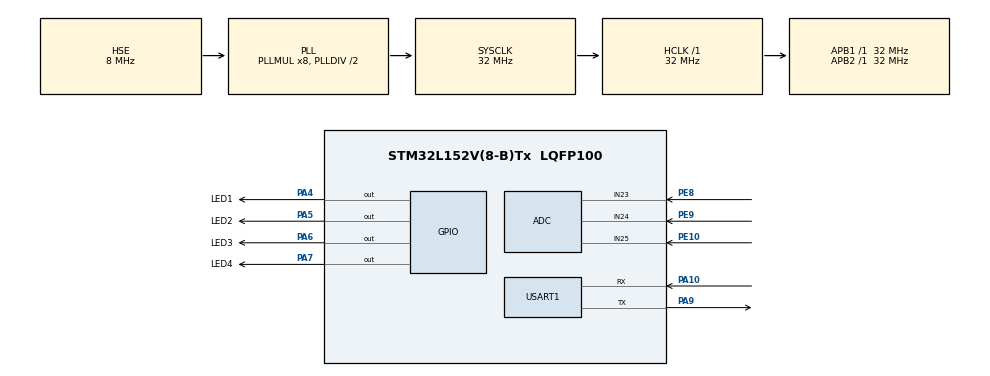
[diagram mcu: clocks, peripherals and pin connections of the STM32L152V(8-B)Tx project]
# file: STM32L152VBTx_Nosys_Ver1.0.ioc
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ADC.Channel-8\#ChannelRegularConversion=ADC_CHANNEL_25
ADC.NbrOfConversionFlag=1
ADC.Rank-8\#ChannelRegularConversion=1
ADC.SamplingTime-8\#ChannelRegularConversion=ADC_SAMPLETIME_4CYCLES
Mcu.Family=STM32L1
Mcu.Name=STM32L152V(8-B)Tx
Mcu.Package=LQFP100
NVIC.PriorityGroup=NVIC_PRIORITYGROUP_4
PA10.Mode=Asynchronous
PA10.Signal=USART1_RX
PA4.GPIO_Label=LED1
PA4.GPIO_ModeDefaultOutputPP=GPIO_MODE_OUTPUT_PP
PA4.GPIO_PuPd=GPIO_PULLUP
PA4.GPIO_Speed=GPIO_SPEED_FREQ_LOW
PA4.Signal=GPIO_Output
PA5.GPIO_Label=LED2
PA5.GPIO_PuPd=GPIO_PULLUP
PA5.Signal=GPIO_Output
PA6.GPIO_Label=LED3
PA6.GPIO_PuPd=GPIO_PULLUP
PA6.Signal=GPIO_Output
PA7.GPIO_Label=LED4
PA7.GPIO_PuPd=GPIO_PULLUP
PA7.Signal=GPIO_Output
PA9.Mode=Asynchronous
PA9.Signal=USART1_TX
PE10.Mode=IN25
PE10.Signal=ADC_IN25
PE8.Mode=IN23
PE8.Signal=ADC_IN23
PE9.Mode=IN24
PE9.Signal=ADC_IN24
PH0-OSC_IN.Mode=HSE-External-Oscillator
PH0-OSC_IN.Signal=RCC_OSC_IN
PH1-OSC_OUT.Mode=HSE-External-Oscillator
PH1-OSC_OUT.Signal=RCC_OSC_OUT
ProjectManager.HeapSize=0x200
ProjectManager.StackSize=0x400
ProjectManager.TargetToolchain=MDK-ARM V5
RCC.AHBFreq_Value=32000000
RCC.APB1Freq_Value=32000000
RCC.APB1TimFreq_Value=32000000
RCC.APB2Freq_Value=32000000
RCC.APB2TimFreq_Value=32000000
RCC.HCLKFreq_Value=32000000
RCC.HSE_VALUE=8000000
RCC.HSI_VALUE=16000000
RCC.LSE_VALUE=32768
RCC.MSI_VALUE=2097000
RCC.PLLMUL=RCC_PLL_MUL8
RCC.PLLSourceVirtual=RCC_PLLSOURCE_HSE
RCC.SYSCLKFreq_VALUE=32000000
RCC.SYSCLKSource=RCC_SYSCLKSOURCE_PLLCLK
RCC.USBOutput=32000000
RCC.VCOOutputFreq_Value=64000000
board=STM32L152VBTx_Nosys_Ver1.0

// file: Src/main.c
/**
  ******************************************************************************
  * File Name          : main.c
  * Description        : Main program body
  ******************************************************************************
  *
  * COPYRIGHT(c) 2017 STMicroelectronics
  *
  * Redistribution and use in source and binary forms, with or without modification,
  * are permitted provided that the following conditions are met:
  *   1. Redistributions of source code must retain the above copyright notice,
  *      this list of conditions and the following disclaimer.
  *   2. Redistributions in binary form must reproduce the above copyright notice,
  *      this list of conditions and the following disclaimer in the documentation
  *      and/or other materials provided with the distribution.
  *   3. Neither the name of STMicroelectronics nor the names of its contributors
  *      may be used to endorse or promote products derived from this software
  *      without specific prior written permission.
  *
  * THIS SOFTWARE IS PROVIDED BY THE COPYRIGHT HOLDERS AND CONTRIBUTORS "AS IS"
  * AND ANY EXPRESS OR IMPLIED WARRANTIES, INCLUDING, BUT NOT LIMITED TO, THE
  * IMPLIED WARRANTIES OF MERCHANTABILITY AND FITNESS FOR A PARTICULAR PURPOSE ARE
  * DISCLAIMED. IN NO EVENT SHALL THE COPYRIGHT HOLDER OR CONTRIBUTORS BE LIABLE
  * FOR ANY DIRECT, INDIRECT, INCIDENTAL, SPECIAL, EXEMPLARY, OR CONSEQUENTIAL
  * DAMAGES (INCLUDING, BUT NOT LIMITED TO, PROCUREMENT OF SUBSTITUTE GOODS OR
  * SERVICES; LOSS OF USE, DATA, OR PROFITS; OR BUSINESS INTERRUPTION) HOWEVER
  * CAUSED AND ON ANY THEORY OF LIABILITY, WHETHER IN CONTRACT, STRICT LIABILITY,
  * OR TORT (INCLUDING NEGLIGENCE OR OTHERWISE) ARISING IN ANY WAY OUT OF THE USE
  * OF THIS SOFTWARE, EVEN IF ADVISED OF THE POSSIBILITY OF SUCH DAMAGE.
  *
  ******************************************************************************
  */
#include "main.h"
#include "stm32l1xx_hal.h"
#include "adc.h"
#include "usart.h"
#include "gpio.h"

/* USER CODE BEGIN PV */
/* Private variables ---------------------------------------------------------*/

/* USER CODE END PV */

void SystemClock_Config(void);
void Error_Handler(void);

/* USER CODE BEGIN PFP */
/* Private function prototypes -----------------------------------------------*/

/* USER CODE END PFP */

int main(void)
{

  /* USER CODE BEGIN 1 */
	uint8_t u8DataSend[64] = "Hello the world \n";
  /* USER CODE END 1 */

  /* MCU Configuration----------------------------------------------------------*/

  /* Reset of all peripherals, Initializes the Flash interface and the Systick. */
  HAL_Init();

  /* Configure the system clock */
  SystemClock_Config();

  /* Initialize all configured peripherals */
  MX_GPIO_Init();
  MX_ADC_Init();
  MX_USART1_UART_Init();

  /* USER CODE BEGIN 2 */
  //why leave my love?
  /* USER CODE END 2 */

  /* Infinite loop */
  while (1)
  {
		  HAL_Delay(100);
			HAL_GPIO_TogglePin(GPIOA, LED1_Pin);
		  HAL_GPIO_TogglePin(GPIOA, LED2_Pin);
		  HAL_Delay(100);

		  HAL_UART_Transmit(&huart1, u8DataSend, sizeof(u8DataSend), 1000);
      HAL_Delay(1000);

  }

}

/** System Clock Configuration
*/
void SystemClock_Config(void)
{

  RCC_OscInitTypeDef RCC_OscInitStruct;
  RCC_ClkInitTypeDef RCC_ClkInitStruct;

    /**Configure the main internal regulator output voltage
    */
  __HAL_PWR_VOLTAGESCALING_CONFIG(PWR_REGULATOR_VOLTAGE_SCALE1);

    /**Initializes the CPU, AHB and APB busses clocks
    */
  RCC_OscInitStruct.OscillatorType = RCC_OSCILLATORTYPE_HSI|RCC_OSCILLATORTYPE_HSE;
  RCC_OscInitStruct.HSEState = RCC_HSE_ON;
  RCC_OscInitStruct.HSIState = RCC_HSI_ON;
  RCC_OscInitStruct.HSICalibrationValue = 16;
  RCC_OscInitStruct.PLL.PLLState = RCC_PLL_ON;
  RCC_OscInitStruct.PLL.PLLSource = RCC_PLLSOURCE_HSE;
  RCC_OscInitStruct.PLL.PLLMUL = RCC_PLL_MUL8;
  RCC_OscInitStruct.PLL.PLLDIV = RCC_PLL_DIV2;
  if (HAL_RCC_OscConfig(&RCC_OscInitStruct) != HAL_OK)
  {
    Error_Handler();
  }

    /**Initializes the CPU, AHB and APB busses clocks
    */
  RCC_ClkInitStruct.ClockType = RCC_CLOCKTYPE_HCLK|RCC_CLOCKTYPE_SYSCLK
                              |RCC_CLOCKTYPE_PCLK1|RCC_CLOCKTYPE_PCLK2;
  RCC_ClkInitStruct.SYSCLKSource = RCC_SYSCLKSOURCE_PLLCLK;
  RCC_ClkInitStruct.AHBCLKDivider = RCC_SYSCLK_DIV1;
  RCC_ClkInitStruct.APB1CLKDivider = RCC_HCLK_DIV1;
  RCC_ClkInitStruct.APB2CLKDivider = RCC_HCLK_DIV1;

  if (HAL_RCC_ClockConfig(&RCC_ClkInitStruct, FLASH_LATENCY_1) != HAL_OK)
  {
    Error_Handler();
  }

    /**Configure the Systick interrupt time
    */
  HAL_SYSTICK_Config(HAL_RCC_GetHCLKFreq()/1000);

    /**Configure the Systick
    */
  HAL_SYSTICK_CLKSourceConfig(SYSTICK_CLKSOURCE_HCLK);

  /* SysTick_IRQn interrupt configuration */
  HAL_NVIC_SetPriority(SysTick_IRQn, 0, 0);
}

void Error_Handler(void)
{
  while(1)
  {
  }
}

/************************ (C) COPYRIGHT STMicroelectronics *****END OF FILE****/
